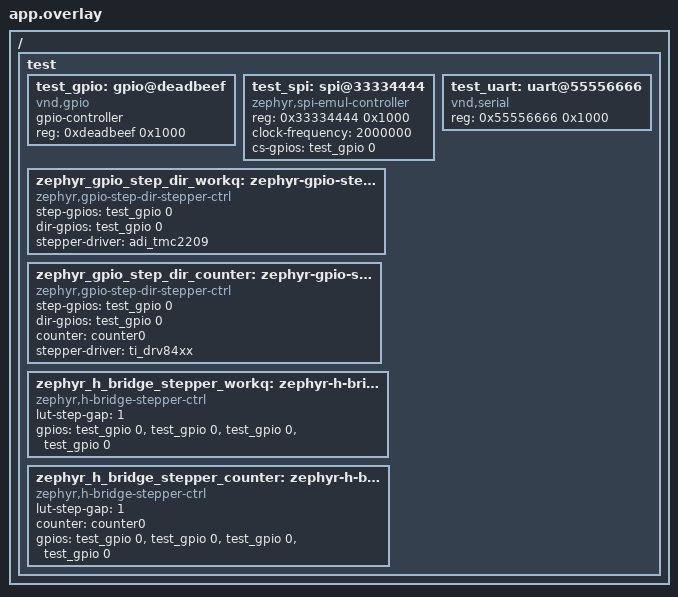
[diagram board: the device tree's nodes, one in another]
/*
 * SPDX-FileCopyrightText: Copyright (c) 2024 Carl Zeiss Meditec AG
 * SPDX-License-Identifier: Apache-2.0
 */

/ {
	test {
		#address-cells = <1>;
		#size-cells = <1>;

		test_gpio: gpio@deadbeef {
			compatible = "vnd,gpio";
			gpio-controller;
			reg = <0xdeadbeef 0x1000>;
			#gpio-cells = <0x2>;
			status = "okay";

			#include "gpio.dtsi"
		};

		test_spi: spi@33334444 {
			#address-cells = <1>;
			#size-cells = <0>;
			compatible = "zephyr,spi-emul-controller";
			reg = <0x33334444 0x1000>;
			status = "okay";
			clock-frequency = <2000000>;

			/* one entry for every devices at spi.dtsi */
			cs-gpios = <&test_gpio 0 0>;	/* 0x00 */

			#include "spi.dtsi"
		};

		test_uart: uart@55556666 {
			compatible = "vnd,serial";
			reg = <0x55556666 0x1000>;
			status = "okay";

			#include "uart.dtsi"
		};

		zephyr_gpio_step_dir_workq: zephyr-gpio-step-dir {
			compatible = "zephyr,gpio-step-dir-stepper-ctrl";
			step-gpios = <&test_gpio 0 0>;
			dir-gpios = <&test_gpio 0 0>;
			stepper-driver = <&adi_tmc2209>;
		};

		zephyr_gpio_step_dir_counter: zephyr-gpio-step-dir-counter {
			compatible = "zephyr,gpio-step-dir-stepper-ctrl";
			step-gpios = <&test_gpio 0 0>;
			dir-gpios = <&test_gpio 0 0>;
			counter = <&counter0>;
			stepper-driver = <&ti_drv84xx>;
		};

		zephyr_h_bridge_stepper_workq: zephyr-h-bridge-stepper {
			compatible = "zephyr,h-bridge-stepper-ctrl";
			status = "okay";
			lut-step-gap = <1>;
			gpios = <&test_gpio 0 0>,
				<&test_gpio 0 0>,
				<&test_gpio 0 0>,
				<&test_gpio 0 0>;
		};

		zephyr_h_bridge_stepper_counter: zephyr-h-bridge-stepper-counter {
			compatible = "zephyr,h-bridge-stepper-ctrl";
			status = "okay";
			lut-step-gap = <1>;
			counter = <&counter0>;
			gpios = <&test_gpio 0 0>,
				<&test_gpio 0 0>,
				<&test_gpio 0 0>,
				<&test_gpio 0 0>;
		};
	};
};
